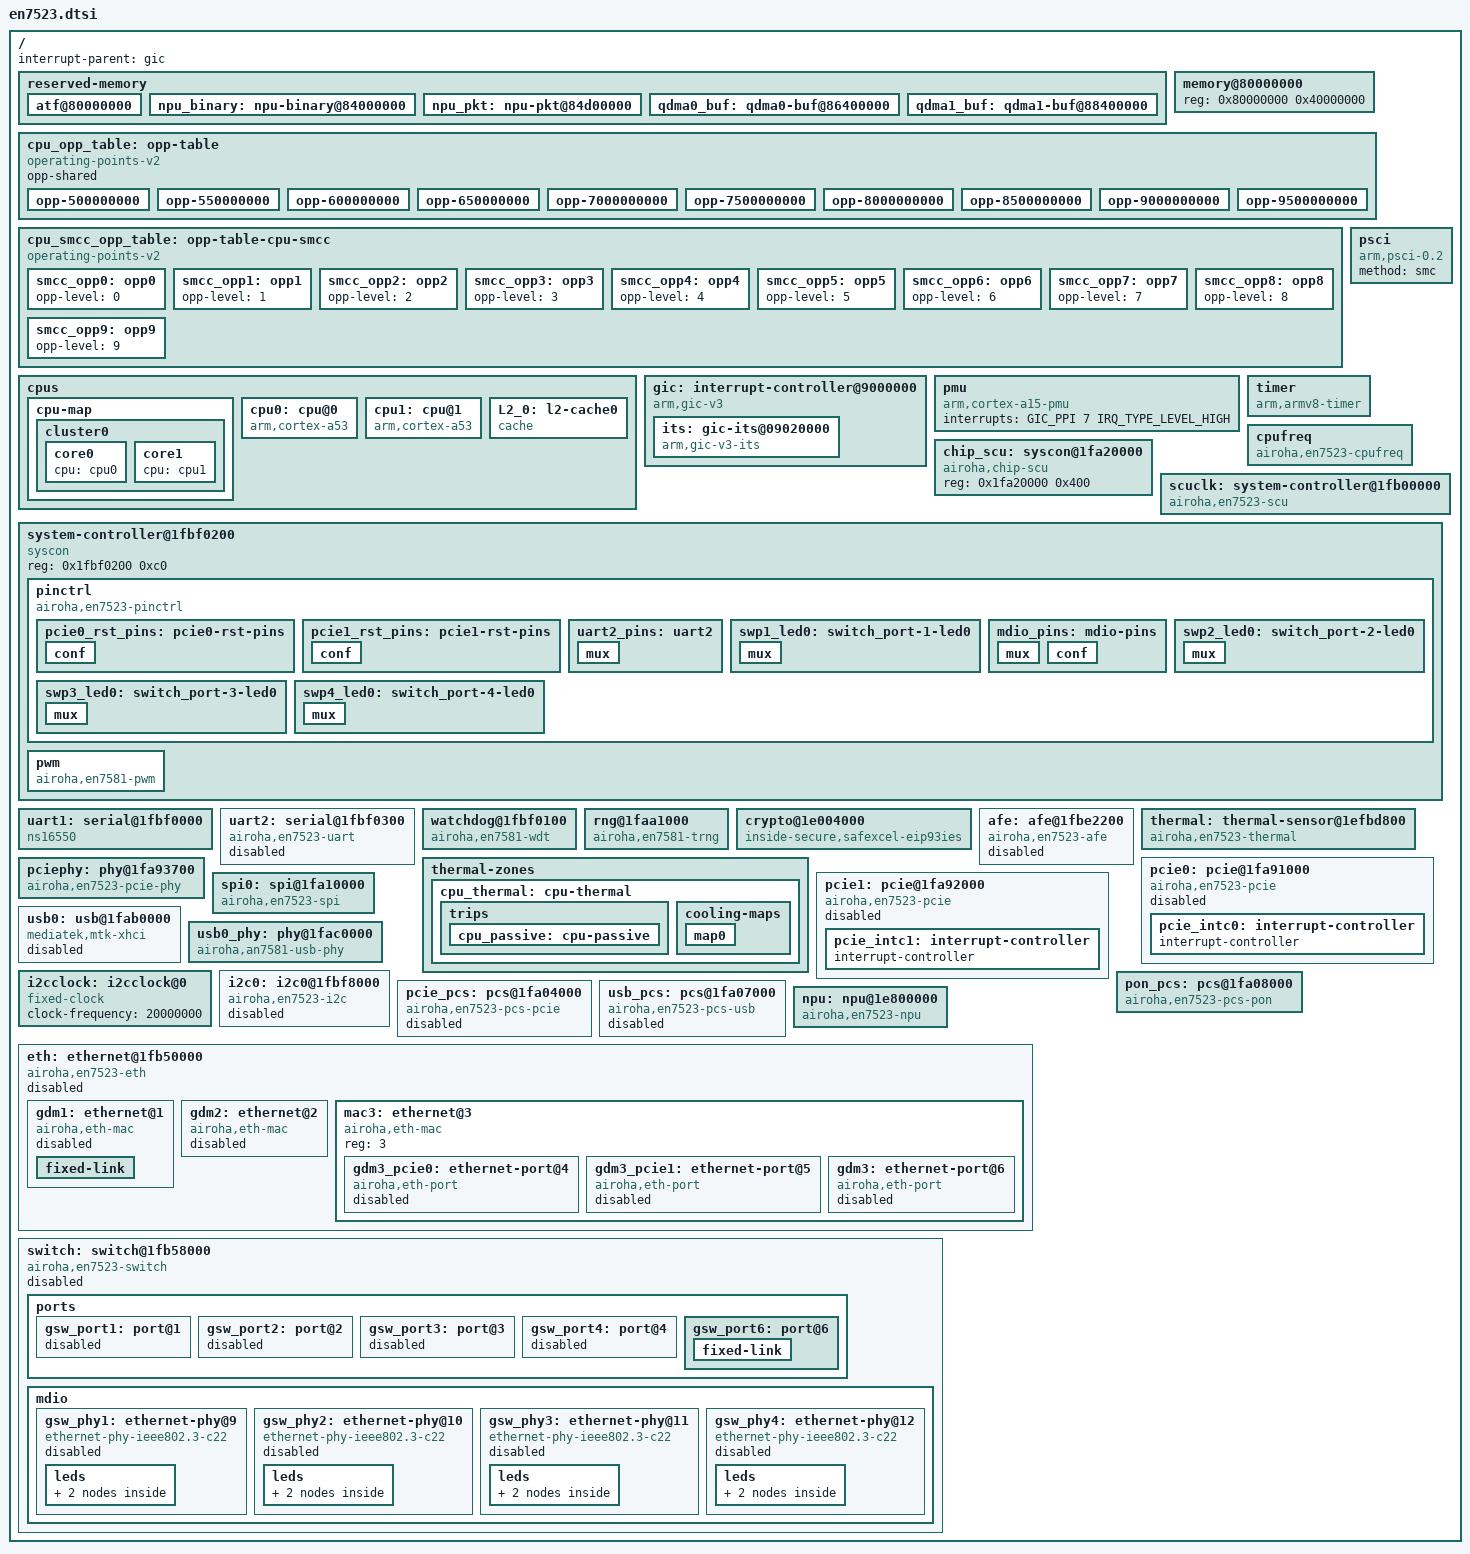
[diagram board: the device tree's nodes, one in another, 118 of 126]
// SPDX-License-Identifier: (GPL-2.0-only OR BSD-2-Clause)

#include <dt-bindings/interrupt-controller/irq.h>
#include <dt-bindings/interrupt-controller/arm-gic.h>
#include <dt-bindings/clock/en7523-clk.h>
#include <dt-bindings/reset/airoha,en7523-reset.h>
#include <dt-bindings/leds/common.h>
#include <dt-bindings/soc/airoha,scu-ssr.h>
#include <dt-bindings/thermal/thermal.h>
#include <dt-bindings/phy/phy.h>
#include <dt-bindings/phy/airoha,an7581-usb-phy.h>

/ {
	interrupt-parent = <&gic>;
	#address-cells = <1>;
	#size-cells = <1>;

	reserved-memory {
		#address-cells = <1>;
		#size-cells = <1>;
		ranges;

		atf@80000000 {
			no-map;
			reg = <0x80000000 0x40000>;
		};

		npu_binary: npu-binary@84000000 {
			no-map;
			reg = <0x84000000 0x00100000>;
		};

		npu_pkt: npu-pkt@84d00000 {
			no-map;
			reg = <0x84d00000 0x01600000>;
		};

		qdma0_buf: qdma0-buf@86400000 {
			no-map;
			reg = <0x86400000 0x02000000>;
		};

		qdma1_buf: qdma1-buf@88400000 {
			no-map;
			reg = <0x88400000 0x01000000>;
		};
	};

	memory@80000000 {
		device_type = "memory";
		reg = <0x80000000 0x40000000>;
	};

	cpu_opp_table: opp-table {
		compatible = "operating-points-v2";
		opp-shared;

		opp-500000000 {
			opp-hz = /bits/ 64 <500000000>;
			required-opps = <&smcc_opp0>;
		};

		opp-550000000 {
			opp-hz = /bits/ 64 <550000000>;
			required-opps = <&smcc_opp1>;
		};

		opp-600000000 {
			opp-hz = /bits/ 64 <600000000>;
			required-opps = <&smcc_opp2>;
		};

		opp-650000000 {
			opp-hz = /bits/ 64 <650000000>;
			required-opps = <&smcc_opp3>;
		};

		opp-7000000000 {
			opp-hz = /bits/ 64 <700000000>;
			required-opps = <&smcc_opp4>;
		};

		opp-7500000000 {
			opp-hz = /bits/ 64 <750000000>;
			required-opps = <&smcc_opp5>;
		};

		opp-8000000000 {
			opp-hz = /bits/ 64 <800000000>;
			required-opps = <&smcc_opp6>;
		};

		opp-8500000000 {
			opp-hz = /bits/ 64 <850000000>;
			required-opps = <&smcc_opp7>;
		};

		opp-9000000000 {
			opp-hz = /bits/ 64 <900000000>;
			required-opps = <&smcc_opp8>;
		};

		opp-9500000000 {
			opp-hz = /bits/ 64 <950000000>;
			required-opps = <&smcc_opp9>;
		};
	};

	cpu_smcc_opp_table: opp-table-cpu-smcc {
		compatible = "operating-points-v2";

		smcc_opp0: opp0 {
			opp-level = <0>;
		};

		smcc_opp1: opp1 {
			opp-level = <1>;
		};

		smcc_opp2: opp2 {
			opp-level = <2>;
		};

		smcc_opp3: opp3 {
			opp-level = <3>;
		};

		smcc_opp4: opp4 {
			opp-level = <4>;
		};

		smcc_opp5: opp5 {
			opp-level = <5>;
		};

		smcc_opp6: opp6 {
			opp-level = <6>;
		};

		smcc_opp7: opp7 {
			opp-level = <7>;
		};

		smcc_opp8: opp8 {
			opp-level = <8>;
		};

		smcc_opp9: opp9 {
			opp-level = <9>;
		};
	};

	psci {
		compatible = "arm,psci-0.2";
		method = "smc";
	};

	cpus {
		#address-cells = <1>;
		#size-cells = <0>;

		cpu-map {
			cluster0 {
				core0 {
					cpu = <&cpu0>;
				};
				core1 {
					cpu = <&cpu1>;
				};
			};
		};

		cpu0: cpu@0 {
			device_type = "cpu";
			compatible = "arm,cortex-a53";
			reg = <0x0>;
			operating-points-v2 = <&cpu_opp_table>;
			enable-method = "psci";
			clocks = <&cpufreq>;
			clock-names = "cpu";
			power-domains = <&cpufreq>;
			power-domain-names = "perf";
			next-level-cache = <&L2_0>;
			#cooling-cells = <2>;
		};

		cpu1: cpu@1 {
			device_type = "cpu";
			compatible = "arm,cortex-a53";
			reg = <0x1>;
			operating-points-v2 = <&cpu_opp_table>;
			enable-method = "psci";
			clocks = <&cpufreq>;
			clock-names = "cpu";
			power-domains = <&cpufreq>;
			power-domain-names = "perf";
			next-level-cache = <&L2_0>;
			#cooling-cells = <2>;
		};

		L2_0: l2-cache0 {
			compatible = "cache";
		};
	};

	gic: interrupt-controller@9000000 {
		compatible = "arm,gic-v3";
		interrupt-controller;
		#interrupt-cells = <3>;
		#address-cells = <1>;
		#size-cells = <1>;
		reg = <0x09000000 0x20000>,
		      <0x09080000 0x80000>,
		      <0x09400000 0x2000>,
		      <0x09500000 0x2000>,
		      <0x09600000 0x20000>;
		interrupts = <GIC_PPI 9 IRQ_TYPE_LEVEL_LOW>;

		its: gic-its@09020000 {
			compatible = "arm,gic-v3-its";
			msi-controller;
			#msi-cell = <1>;
			reg = <0x090200000 0x20000>;
		};
	};

	pmu {
		compatible = "arm,cortex-a15-pmu";
		interrupts = <GIC_PPI 7 IRQ_TYPE_LEVEL_HIGH>;
	};

	timer {
		compatible = "arm,armv8-timer";
		interrupt-parent = <&gic>;
		interrupts = <GIC_PPI 13 IRQ_TYPE_LEVEL_LOW>,
			     <GIC_PPI 14 IRQ_TYPE_LEVEL_LOW>,
			     <GIC_PPI 11 IRQ_TYPE_LEVEL_LOW>,
			     <GIC_PPI 10 IRQ_TYPE_LEVEL_LOW>;
	};

	cpufreq: cpufreq {
		compatible = "airoha,en7523-cpufreq";
		reg = <0x1efbe000 0x800>,
		      <0x1fa20000 0x2c0>;
		reg-names = "mcucfg", "chip-scu";

		airoha,chip-scu = <&chip_scu>;
		operating-points-v2 = <&cpu_smcc_opp_table>;

		#power-domain-cells = <0>;
		#clock-cells = <0>;
	};

	chip_scu: syscon@1fa20000 {
		compatible = "airoha,chip-scu", "syscon";
		reg = <0x1fa20000 0x400>;
	};

	scuclk: system-controller@1fb00000 {
		compatible = "airoha,en7523-scu", "syscon";
		reg = <0x1fb00000 0x1000>;
		airoha,chip-scu = <&chip_scu>;
		#clock-cells = <1>;
		#reset-cells = <1>;
	};

	system-controller@1fbf0200 {
		compatible = "syscon", "simple-mfd";
		reg = <0x1fbf0200 0xc0>;

		pinctrl: pinctrl {
			compatible = "airoha,en7523-pinctrl";

			interrupt-parent = <&gic>;
			interrupts = <GIC_SPI 26 IRQ_TYPE_LEVEL_HIGH>;

			airoha,chip-scu = <&chip_scu>;

			gpio-controller;
			#gpio-cells = <2>;

			interrupt-controller;
			#interrupt-cells = <2>;

			gpio-ranges = <&pinctrl 0 12 28>;

			pcie0_rst_pins: pcie0-rst-pins {
				conf {
					pins = "pcie_reset0";
					drive-open-drain = <1>;
				};
			};

			pcie1_rst_pins: pcie1-rst-pins {
				conf {
					pins = "pcie_reset1";
					drive-open-drain = <1>;
				};
			};

			uart2_pins: uart2 {
				mux {
					function = "uart";
					groups = "uart2";
				};
			};

			swp1_led0: switch_port-1-led0 {
				mux {
					function = "phy1_led0";
					pins = "gpio22";
				};
			};

			mdio_pins: mdio-pins {
				mux {
					function = "mdio";
					groups = "mdio";
				};

				conf {
					pins = "gpio9";
					output-high;
				};
			};

			swp2_led0: switch_port-2-led0 {
				mux {
					function = "phy2_led0";
					pins = "gpio23";
				};
			};

			swp3_led0: switch_port-3-led0 {
				mux {
					function = "phy3_led0";
					pins = "gpio24";
				};
			};

			swp4_led0: switch_port-4-led0 {
				mux {
					function = "phy4_led0";
					pins = "gpio25";
				};
			};
		};

		pwm: pwm {
			compatible = "airoha,en7581-pwm";

			#pwm-cells = <3>;
		};
	};

	uart1: serial@1fbf0000 {
		compatible = "ns16550";
		reg = <0x1fbf0000 0x30>;
		reg-io-width = <4>;
		reg-shift = <2>;
		interrupts = <GIC_SPI 18 IRQ_TYPE_LEVEL_HIGH>;
		clock-frequency = <1843200>;
	};

	uart2: serial@1fbf0300 {
		compatible = "airoha,en7523-uart";
		reg = <0x1fbf0300 0x30>;
		interrupts = <GIC_SPI 32 IRQ_TYPE_LEVEL_HIGH>;

		pinctrl-names = "default";
		pinctrl-0 = <&uart2_pins>;

		status = "disabled";
	};

	watchdog@1fbf0100 {
		compatible = "airoha,en7581-wdt";
		reg = <0x1fbf0100 0x40>;

		interrupts = <GIC_SPI 20 IRQ_TYPE_LEVEL_HIGH>,
		             <GIC_SPI 21 IRQ_TYPE_LEVEL_HIGH>,
		             <GIC_SPI 22 IRQ_TYPE_LEVEL_HIGH>,
		             <GIC_SPI 25 IRQ_TYPE_LEVEL_HIGH>;

		clocks = <&scuclk EN7523_CLK_BUS>;
		clock-names = "bus";

		#interrupt-cells = <1>;
	};

	rng@1faa1000 {
		compatible = "airoha,en7581-trng";
		reg = <0x1faa1000 0xc04>;
		interrupts = <GIC_SPI 35 IRQ_TYPE_LEVEL_HIGH>;
	};

	crypto@1e004000 {
		compatible = "inside-secure,safexcel-eip93ies";
		reg = <0x1fb70000 0x1000>;
		interrupts = <GIC_SPI 44 IRQ_TYPE_LEVEL_HIGH>;
	};

	afe: afe@1fbe2200 {
		compatible = "airoha,en7523-afe";
		reg = <0x1fbe2200 0x9000>;

		interrupts = <GIC_SPI 48 IRQ_TYPE_LEVEL_HIGH>;
		status = "disabled";
	};

	thermal: thermal-sensor@1efbd800 {
		compatible = "airoha,en7523-thermal";
		reg = <0x1efbd000 0x0fff>;
		interrupts = <GIC_SPI 23 IRQ_TYPE_LEVEL_HIGH>;
		airoha,chip-scu = <&chip_scu>;

		#thermal-sensor-cells = <1>;
	};

	thermal-zones {
		cpu_thermal: cpu-thermal {
			polling-delay-passive = <250>;
			polling-delay = <1000>;
			thermal-sensors = <&thermal 0>;
			trips {
				cpu_passive: cpu-passive {
					temperature = <300000>;
					hysteresis = <0>;
					type = "passive";
				};
			};
			cooling-maps {
				map0 {
					trip = <&cpu_passive>;
					cooling-device = <&cpu0 THERMAL_NO_LIMIT THERMAL_NO_LIMIT>,
							 <&cpu1 THERMAL_NO_LIMIT THERMAL_NO_LIMIT>;
				};
			};
		};
	};

	pciephy: phy@1fa93700 {
		compatible = "airoha,en7523-pcie-phy";
		reg = <0x1fa93700 0x568>,
		      <0x1fa95700 0x568>;
		reg-names = "pcie0", "pcie1";
		#phy-cells = <0>;
		airoha,chip_scu = <&chip_scu>;
	};

	pcie0: pcie@1fa91000 {
		compatible = "airoha,en7523-pcie", "mediatek,mt7622-pcie";
		device_type = "pci";
		reg = <0x1fa91000 0x1000>;
		reg-names = "port0";
		linux,pci-domain = <0>;
		#address-cells = <3>;
		#size-cells = <2>;
		interrupts = <GIC_SPI 39 IRQ_TYPE_LEVEL_HIGH>;
		interrupt-names = "pcie_irq";
		clocks = <&scuclk EN7523_CLK_PCIE>;
		clock-names = "sys_ck0";
		bus-range = <0x00 0xff>;
		ranges = <0x82000000 0 0x20000000 0x20000000 0 0x2000000>;
		status = "disabled";

		pinctrl-names = "default";
		pinctrl-0 = <&pcie0_rst_pins>;

		airoha,npu = <&npu>;

		phys = <&pciephy>;
		phy-names = "pcie-phy";

		#interrupt-cells = <1>;
		interrupt-map-mask = <0 0 0 7>;
		interrupt-map = <0 0 0 1 &pcie_intc0 0>,
				<0 0 0 2 &pcie_intc0 1>,
				<0 0 0 3 &pcie_intc0 2>,
				<0 0 0 4 &pcie_intc0 3>;
		pcie_intc0: interrupt-controller {
			interrupt-controller;
			#address-cells = <0>;
			#interrupt-cells = <1>;
		};
	};

	pcie1: pcie@1fa92000 {
		compatible = "airoha,en7523-pcie", "mediatek,mt7622-pcie";
		device_type = "pci";
		reg = <0x1fa92000 0x1000>;
		reg-names = "port1";
		linux,pci-domain = <1>;
		#address-cells = <3>;
		#size-cells = <2>;
		interrupts = <GIC_SPI 40 IRQ_TYPE_LEVEL_HIGH>;
		interrupt-names = "pcie_irq";
		clocks = <&scuclk EN7523_CLK_PCIE>;
		clock-names = "sys_ck1";
		bus-range = <0x00 0xff>;
		ranges = <0x82000000 0 0x22000000 0x22000000 0 0x2000000>;
		status = "disabled";

		pinctrl-names = "default";
		pinctrl-0 = <&pcie1_rst_pins>;

		airoha,npu = <&npu>;

		phys = <&pciephy>;
		phy-names = "pcie-phy";

		#interrupt-cells = <1>;
		interrupt-map-mask = <0 0 0 7>;
		interrupt-map = <0 0 0 1 &pcie_intc1 0>,
				<0 0 0 2 &pcie_intc1 1>,
				<0 0 0 3 &pcie_intc1 2>,
				<0 0 0 4 &pcie_intc1 3>;
		pcie_intc1: interrupt-controller {
			interrupt-controller;
			#address-cells = <0>;
			#interrupt-cells = <1>;
		};
	};

	spi0: spi@1fa10000 {
		compatible = "airoha,en7523-spi", "airoha,en7581-snand";
		reg = <0x1fa10000 0x140>,
		      <0x1fa11000 0x160>;

		interrupts = <GIC_SPI 51 IRQ_TYPE_LEVEL_HIGH>;
		clocks = <&scuclk EN7523_CLK_SPI>;
		clock-names = "spi";

		airoha,scu = <&scuclk>, <&chip_scu>;
		airoha,scu-names = "scuclk", "chip-scu";

		#address-cells = <1>;
		#size-cells = <0>;
	};

	usb0: usb@1fab0000 {
		compatible = "mediatek,mtk-xhci";
		reg = <0x1fab0000 0x3e00>,
		      <0x1fab3e00 0x100>;
		reg-names = "mac", "ippc";
		interrupts = <GIC_SPI 33 IRQ_TYPE_LEVEL_HIGH>;

		phys = <&usb0_phy PHY_TYPE_USB2>, <&usb0_phy PHY_TYPE_USB3>;

		status = "disabled";
	};

	usb0_phy: phy@1fac0000 {
		compatible = "airoha,an7581-usb-phy";
		reg = <0x1fad0000 0x1fff>;

		airoha,scu = <&scuclk>;
		airoha,usb2-monitor-clk-sel = <AIROHA_USB2_MONCLK_SEL1>;
		airoha,serdes-port = <AIROHA_SCU_SERDES_USB1>;

		#phy-cells = <1>;
	};

	i2cclock: i2cclock@0 {
		#clock-cells = <0>;
		compatible = "fixed-clock";

		/* 20 MHz */
		clock-frequency = <20000000>;
	};

	i2c0: i2c0@1fbf8000 {
		compatible = "airoha,en7523-i2c";
		reg = <0x1fbf8000 0x100>;

		clocks = <&i2cclock>;

		/* 100 kHz */
		clock-frequency = <100000>;
		#address-cells = <1>;
		#size-cells = <0>;

		status = "disabled";
	};

	pon_pcs: pcs@1fa08000 {
		compatible = "airoha,en7523-pcs-pon";
		reg = <0x1fa60000 0x1000>,
		      <0x1fa65100 0x4a0>,
		      <0x1fa65a00 0x1ac>,
		      <0x1fa65e00 0x64>,
		      <0x1fa66000 0xdc>,
		      <0x1faf0000 0x800>,
		      <0x1faf3000 0x1000>,
		      <0x1faf4000 0x1000>;
		reg-names = "pcs-mac", "pcs1", "pcs2", "an", "rate-adapt",
			    "pon-phy0", "pon-phy1", "pon-phy2";

		resets = <&scuclk EN7523_XPON_MAC_RST>,
			 <&scuclk EN7523_XPON_PHY_RST>;
		reset-names = "mac", "phy";

		airoha,scu = <&scuclk>;

		#pcs-cells = <0>;
	};

	pcie_pcs: pcs@1fa04000 {
		compatible = "airoha,en7523-pcs-pcie";
		reg = <0x1fa70000 0x1000>, /* PCIE0 */
		      <0x1fa71000 0x1000>, /* PCIE1 */
		      /* PCIE0 */
		      <0x1fa72100 0x4a0>,
		      <0x1fa72a00 0x160>,
		      <0x1fa72000 0x64>,
		      <0x1fa72600 0xdc>,
		      <0x1fa72c00 0x3b0>,
		      /* PCIE1 */
		      <0x1fa77100 0x4a0>,
		      <0x1fa77a00 0x160>,
		      <0x1fa77000 0x64>,
		      <0x1fa77600 0xdc>,
		      <0x1fa77c00 0x3b0>;
		reg-names = "pcs-mac0", "pcs-mac1",
			    "pcie0-pcs1", "pcie0-pcs2", "pcie0-an",
			    "pcie0-rate-adapt", "pcie0-phya",
			    "pcie1-pcs1", "pcie1-pcs2", "pcie1-an",
			    "pcie1-rate-adapt", "pcie1-phya";

		airoha,scu = <&scuclk>;
		#pcs-cells = <1>;
		status = "disabled";
	};

	usb_pcs: pcs@1fa07000 {
		compatible = "airoha,en7523-pcs-usb";
		reg = <0x1fa80000 0x1000>,
		      <0x1fa81100 0x4a0>,
		      <0x1fa81a00 0x160>,
		      <0x1fa81000 0x64>,
		      <0x1fa81600 0xdc>,
		      <0x1fa81c00 0x3b0>;
		reg-names = "pcs-mac", "pcs1", "pcs2", "an",
			    "rate-adapt", "phya";

		phys = <&usb0_phy PHY_TYPE_USB3>;

		airoha,scu = <&scuclk>;
		#pcs-cells = <0>;
		status = "disabled";
	};

	npu: npu@1e800000 {
		compatible = "airoha,en7523-npu";
		reg = <0x1e900000 0x313000>; /* NPU 16K SRAM, Registers */
		interrupts = <GIC_SPI 125 IRQ_TYPE_LEVEL_HIGH>, /* mbox2host irq */
		             <GIC_SPI 118 IRQ_TYPE_LEVEL_HIGH>, /* 102+16 tr done */
		             <GIC_SPI 119 IRQ_TYPE_LEVEL_HIGH>,
		             <GIC_SPI 120 IRQ_TYPE_LEVEL_HIGH>,
		             <GIC_SPI 121 IRQ_TYPE_LEVEL_HIGH>, /* 105+16 hadap irq0 */
		             <GIC_SPI 122 IRQ_TYPE_LEVEL_HIGH>,
		             <GIC_SPI 123 IRQ_TYPE_LEVEL_HIGH>;

		airoha,scu = <&scuclk>;
		memory-region = <&npu_binary>, <&npu_pkt>;
		memory-region-names = "binary", "pkt";
		airoha,enable_npu_tx_uart; /* Enable to debug NPU Calls */
	};

	eth: ethernet@1fb50000 {
		compatible = "airoha,en7523-eth";
		status = "disabled";
		reg = <0x1fb50000 0x2600>,
		      <0x1fb54000 0x2000>,
		      <0x1fb56000 0x2000>,
		      <0x1fbf9000 0x1000>;
		reg-names = "fe", "qdma0", "qdma1", "gdmp";

		resets = <&scuclk EN7523_FE_RST>,
		         <&scuclk EN7523_FE_PDMA_RST>,
		         <&scuclk EN7523_FE_QDMA_RST>,
		         <&scuclk EN7523_DUAL_HSI0_MAC_RST>,
		         <&scuclk EN7523_DUAL_HSI1_MAC_RST>,
		         <&scuclk EN7523_HSI_MAC_RST>,
		         <&scuclk EN7523_GDMP_RST>;
		reset-names = "fe", "pdma", "qdma",
		              "hsi0-mac", "hsi1-mac", "hsi-mac",
									"gdmp";

		interrupts = <GIC_SPI 37 IRQ_TYPE_LEVEL_HIGH>,
		             <GIC_SPI 55 IRQ_TYPE_LEVEL_HIGH>,
		             <GIC_SPI 56 IRQ_TYPE_LEVEL_HIGH>,
		             <GIC_SPI 57 IRQ_TYPE_LEVEL_HIGH>,
		             <GIC_SPI 38 IRQ_TYPE_LEVEL_HIGH>,
		             <GIC_SPI 58 IRQ_TYPE_LEVEL_HIGH>,
		             <GIC_SPI 59 IRQ_TYPE_LEVEL_HIGH>,
		             <GIC_SPI 60 IRQ_TYPE_LEVEL_HIGH>,
		             <GIC_SPI 49 IRQ_TYPE_LEVEL_HIGH>,
		             <GIC_SPI 64 IRQ_TYPE_LEVEL_HIGH>;

		memory-region = <&qdma0_buf>, <&qdma1_buf>;
		memory-region-names = "qdma0-buf", "qdma1-buf";

		airoha,npu = <&npu>;

		#address-cells = <1>;
		#size-cells = <0>;

		gdm1: ethernet@1 {
			compatible = "airoha,eth-mac";
			reg = <1>;
			phy-mode = "internal";
			status = "disabled";

			fixed-link {
				speed = <10000>;
				full-duplex;
				pause;
			};
		};

		gdm2: ethernet@2 {
			compatible = "airoha,eth-mac";
			reg = <2>;
			pcs-handle = <&pon_pcs>;

			status = "disabled";
		};

		mac3: ethernet@3 {
			compatible = "airoha,eth-mac";
			reg = <3>;

			#address-cells = <1>;
			#size-cells = <0>;

			gdm3_pcie0: ethernet-port@4 {
				compatible = "airoha,eth-port";
				reg = <4>;
				pcs-handle = <&pcie_pcs 0>;
				status = "disabled";
			};

			gdm3_pcie1: ethernet-port@5 {
				compatible = "airoha,eth-port";
				reg = <5>;
				pcs-handle = <&pcie_pcs 1>;
				status = "disabled";
			};

			gdm3: ethernet-port@6 {
				compatible = "airoha,eth-port";
				reg = <6>;
				pcs-handle = <&usb_pcs>;
				status = "disabled";
			};
		};
	};

	switch: switch@1fb58000 {
		compatible = "airoha,en7523-switch";
		reg = <0x1fb58000 0x8000>;
		resets = <&scuclk EN7523_GSW_RST>;

		interrupt-controller;
		#interrupt-cells = <1>;
		interrupt-parent = <&gic>;
		interrupts = <GIC_SPI 31 IRQ_TYPE_LEVEL_HIGH>;

		status = "disabled";

		pinctrl-names = "default";
		pinctrl-0 = <&mdio_pins>;

		#address-cells = <1>;
		#size-cells = <1>;

		ports {
			#address-cells = <1>;
			#size-cells = <0>;

			gsw_port1: port@1 {
				reg = <1>;
				phy-mode = "internal";
				phy-handle = <&gsw_phy1>;
				status = "disabled";
			};

			gsw_port2: port@2 {
				reg = <2>;
				phy-mode = "internal";
				phy-handle = <&gsw_phy2>;
				status = "disabled";
			};

			gsw_port3: port@3 {
				reg = <3>;
				phy-mode = "internal";
				phy-handle = <&gsw_phy3>;
				status = "disabled";
			};

			gsw_port4: port@4 {
				reg = <4>;
				phy-mode = "internal";
				phy-handle = <&gsw_phy4>;
				status = "disabled";
			};

			gsw_port6: port@6 {
				reg = <6>;
				ethernet = <&gdm1>;
				phy-mode = "internal";

				fixed-link {
					speed = <10000>;
					full-duplex;
					pause;
				};
			};
		};

		mdio: mdio {
			#address-cells = <1>;
			#size-cells = <0>;

			gsw_phy1: ethernet-phy@9 {
				compatible = "ethernet-phy-ieee802.3-c22";
				reg = <9>;
				phy-mode = "internal";
				status = "disabled";

				pinctrl-names = "gbe-led";
				pinctrl-0 = <&swp1_led0>;
				airoha,scu = <&scuclk>;

				leds {
					#address-cells = <1>;
					#size-cells = <0>;

					gsw_phy1_led0: led0@0 {
						reg = <0>;
						function = LED_FUNCTION_LAN;
						status = "disabled";
						active-low;
					};

					gsw_phy1_led1: led1@1 {
						reg = <1>;
						status = "disabled";
						function = LED_FUNCTION_ACTIVITY;
						active-low;
					};
				};
			};

			gsw_phy2: ethernet-phy@10 {
				compatible = "ethernet-phy-ieee802.3-c22";
				reg = <10>;
				phy-mode = "internal";
				status = "disabled";

				pinctrl-names = "gbe-led";
				pinctrl-0 = <&swp2_led0>;
				airoha,scu = <&scuclk>;

				leds {
					#address-cells = <1>;
					#size-cells = <0>;

					gsw_phy2_led0: led0@0 {
						reg = <0>;
						function = LED_FUNCTION_LAN;
						status = "disabled";
						active-low;
					};

					gsw_phy2_led1: led1@1 {
						reg = <1>;
						status = "disabled";
						function = LED_FUNCTION_ACTIVITY;
						active-low;
					};
				};
			};

			gsw_phy3: ethernet-phy@11 {
				compatible = "ethernet-phy-ieee802.3-c22";
				reg = <11>;
				phy-mode = "internal";
				status = "disabled";

				pinctrl-names = "gbe-led";
				pinctrl-0 = <&swp3_led0>;
				airoha,scu = <&scuclk>;

				leds {
					#address-cells = <1>;
					#size-cells = <0>;

					gsw_phy3_led0: led0@0 {
						reg = <0>;
						function = LED_FUNCTION_LAN;
						status = "disabled";
						active-low;
					};

					gsw_phy3_led1: led1@1 {
						reg = <1>;
						status = "disabled";
						function = LED_FUNCTION_ACTIVITY;
						active-low;
					};
				};
			};

			gsw_phy4: ethernet-phy@12 {
				compatible = "ethernet-phy-ieee802.3-c22";
				reg = <12>;
				phy-mode = "internal";
				status = "disabled";

				pinctrl-names = "gbe-led";
				pinctrl-0 = <&swp4_led0>;
				airoha,scu = <&scuclk>;

				leds {
					#address-cells = <1>;
					#size-cells = <0>;

					gsw_phy4_led0: led0@0 {
						reg = <0>;
						function = LED_FUNCTION_LAN;
						status = "disabled";
						active-low;
					};

					gsw_phy4_led1: led1@1 {
						reg = <1>;
						status = "disabled";
						function = LED_FUNCTION_ACTIVITY;
						active-low;
					};
				};
			};
		};
	};
};
